# RockChip_RK3588 register map
Vendor: RockChip Electronics Co., Ltd.; Series: RK3588; File version: 0.1
Registers are 32-bit, read-write, no defined reset value unless marked. A register's access mark holds for its fields unless they carry their own. Offsets are from the block's base; [hi:lo] are bit positions; <NAME> marks a mode.

## CRU_PHP_PPLL
Base 0xFD7C8000
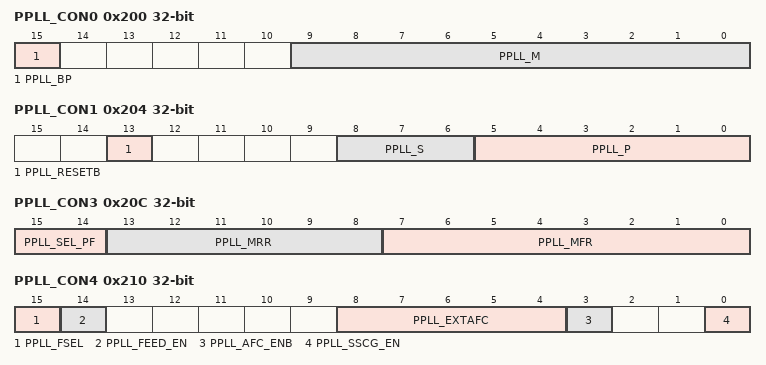
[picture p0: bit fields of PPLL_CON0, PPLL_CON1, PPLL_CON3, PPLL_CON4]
0x200 PPLL_CON0 — PPLL configuration register 0
  [15] PPLL_BP — BYPASS: Bypass mode control signal.
    1=BYPASS (bypass mode is enabled. (FOUT = FIN).); 0=NORMAL (PLL operates normally.)
  [9:0] PPLL_M — M: Division value of the 10-bit programmable main-divider. PLL has to be reset if M value is changed. 64 <= pll_m <= 1023
0x204 PPLL_CON1 — PPLL configuration register 1
  [13] PPLL_RESETB — RESETB: Power down control signal.
    0=NORMAL (RESETB=0 from 1, PLL starts its normal operation after lock time.); 1=POWER_DOWN (RESETB=1, power down mode is enabled and all digital blocks are reset.)
  [8:6] PPLL_S — Division value of the 3-bit programmable scaler. 0 <= pll_s <= 6
  [5:0] PPLL_P — P: Division value of the 6-bit programmable pre-divider. PLL has to be reset if P value is changed. 1 <= pll_p <= 63
0x208 PPLL_CON2 — PPLL configuration register 2
  [15:0] PPLL_K — K: Value of 16-bit DSM. pll_k[15:0] is a two's complement integer.
0x20C PPLL_CON3 — PPLL configuration register 3
  [15:14] PPLL_SEL_PF — SEL_PF: Value of 2-bit modulation method control.
    0=DOWN_SPREAD; 1=UP_SPREAD; 2=CENTER_SPREAD_2 (PLL has to be reset if pll_sel_pf is changed.); 3=CENTER_SPREAD_3 (PLL has to be reset if pll_sel_pf is changed.)
  [13:8] PPLL_MRR — MRR: Value of 6-bit modulation rate control. PLL has to be reset if pll_mrr is changed.
  [7:0] PPLL_MFR — MFR: Value of 8-bit modulation frequency control. PLL has to be reset if pll_mfr is changed.
0x210 PPLL_CON4 — PPLL configuration register 4
  [15] PPLL_FSEL — FSEL: Monitoring pin.
    0=FREF (FEED_OUT = FREF.); 1=FEED (FEED_OUT = FEED.)
  [14] PPLL_FEED_EN — FEED_EN: Monitoring pin.
    0=DISABLED (FEED_OUT is disabled.); 1=ENABLED (FEED_OUT is enabled.)
  [8:4] PPLL_EXTAFC — EXTAFC: Monitoring pin. If pll_afc_enb=1, AFC is disabled and VCO is calibrated manually by pll_extafc[4:0] for the test of VCO range.
  [3] PPLL_AFC_ENB — AFC_ENB: Monitoring pin.
    0=ENABLED (AFC is enabled and VCO is calibrated automatically.); 1=DISABLED (AFC is disabled and VCO is calibrated manually by pll_extafc[4:0] for the test of VCO range.)
  [0] PPLL_SSCG_EN — SSCG_EN: Enable pin for dithered mode.
    0=ENABLE (disable dithered mode.); 1=DISABLE (enable dithered mode.)
0x214 PPLL_CON5 — PPLL configuration register 5
  [0] PPLL_FOUT_MASK — FOUT_MASK: Scaler's re-initialization time control pin.
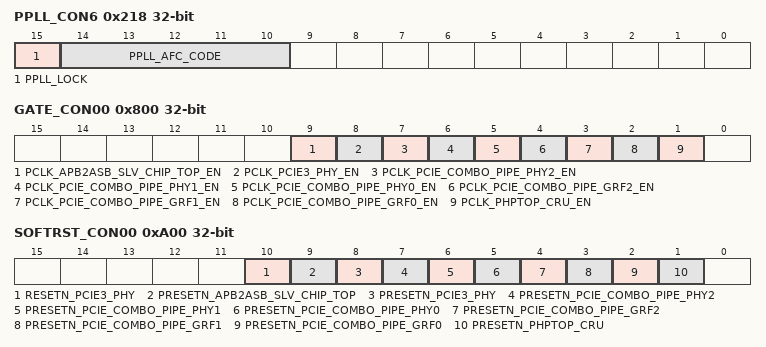
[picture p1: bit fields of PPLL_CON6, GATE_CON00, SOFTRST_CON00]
0x218 PPLL_CON6 — PPLL configuration register 6
  [15] PPLL_LOCK — LOCK: PLL lock flag.
    0=UNLOCKED (PLL is unlocked.); 1=LOCKED (PLL is locked.)
  [14:10] PPLL_AFC_CODE — AFC_CODE: Monitoring pin. Output code of AFC(5 bits).
0x800 GATE_CON00 — Internal clock gate and division register 0
  [all] fields
    0=ENABLE; 1=ENABLE
  [9] PCLK_APB2ASB_SLV_CHIP_TOP_EN — pclk_apb2asb_slv_chip_top clock gating control.
  [8] PCLK_PCIE3_PHY_EN — pclk_pcie3_phy clock gating control.
  [7] PCLK_PCIE_COMBO_PIPE_PHY2_EN — pclk_pcie_combo_pipe_phy2 clock gating control.
  [6] PCLK_PCIE_COMBO_PIPE_PHY1_EN — pclk_pcie_combo_pipe_phy1 clock gating control.
  [5] PCLK_PCIE_COMBO_PIPE_PHY0_EN — pclk_pcie_combo_pipe_phy0 clock gating control.
  [4] PCLK_PCIE_COMBO_PIPE_GRF2_EN — pclk_pcie_combo_pipe_grf2 clock gating control.
  [3] PCLK_PCIE_COMBO_PIPE_GRF1_EN — pclk_pcie_combo_pipe_grf1 clock gating control.
  [2] PCLK_PCIE_COMBO_PIPE_GRF0_EN — pclk_pcie_combo_pipe_grf0 clock gating control.
  [1] PCLK_PHPTOP_CRU_EN — pclk_phptop_cru clock gating control.
0xA00 SOFTRST_CON00 — Internal clock reset register 0
  [10] RESETN_PCIE3_PHY — When high, reset relative logic
  [9] PRESETN_APB2ASB_SLV_CHIP_TOP — When high, reset relative logic
  [8] PRESETN_PCIE3_PHY — When high, reset relative logic
  [7] PRESETN_PCIE_COMBO_PIPE_PHY2 — When high, reset relative logic
  [6] PRESETN_PCIE_COMBO_PIPE_PHY1 — When high, reset relative logic
  [5] PRESETN_PCIE_COMBO_PIPE_PHY0 — When high, reset relative logic
  [4] PRESETN_PCIE_COMBO_PIPE_GRF2 — When high, reset relative logic
  [3] PRESETN_PCIE_COMBO_PIPE_GRF1 — When high, reset relative logic
  [2] PRESETN_PCIE_COMBO_PIPE_GRF0 — When high, reset relative logic
  [1] PRESETN_PHPTOP_CRU — When high, reset relative logic
